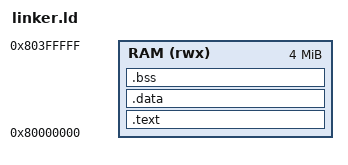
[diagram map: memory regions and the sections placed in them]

OUTPUT_ARCH(riscv)
ENTRY(_start)

MEMORY
{
  RAM (rwx) : ORIGIN = 0x80000000, LENGTH = 4M
}

SECTIONS
{
  .text : {
    KEEP(*(.init))
    *(.text*)
    *(.rodata*)
  } > RAM

  .data : {
    *(.data*)
  } > RAM

  .bss (NOLOAD) : {
    __bss_start__ = .;
    *(.bss*)
    *(COMMON)
    __bss_end__ = .;
  } > RAM

  . = ORIGIN(RAM) + LENGTH(RAM);
  __stack_top = .;
}
